# LPC55S66_cm33_core1 register map
Vendor: nxp.com; File version: 1.0
CPU: CM33 r2p0, little endian, no MPU, no FPU, VTOR, 3 interrupt priority bits
Registers are 32-bit, read-write, reset 0x0 unless marked. A register's access mark holds for its fields unless they carry their own. Offsets are from the block's base; [hi:lo] are bit positions; {n}, {i} and the like mark numbered series.

## UTICK0 — Micro-tick Timer (UTICK)
Base 0x4000E000
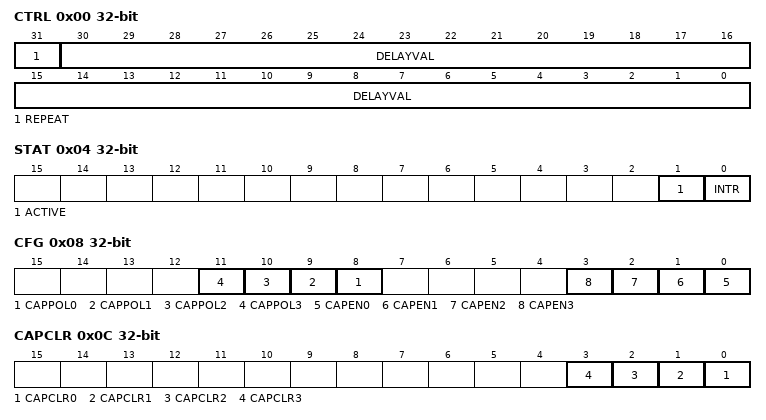
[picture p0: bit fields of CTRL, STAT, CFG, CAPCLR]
0x00 CTRL — Control register.
  [31] REPEAT — Repeat delay. 0 = One-time delay. 1 = Delay repeats continuously.
  [30:0] DELAYVAL — Tick interval value. The delay will be equal to DELAYVAL + 1 periods of the timer clock. The minimum usable value is 1, for a delay of 2 timer clocks. A value of 0 stops the timer.
0x04 STAT — Status register.
  [1] ACTIVE — Active flag. 0 = The Micro-Tick Timer is stopped. 1 = The Micro-Tick Timer is currently active.
  [0] INTR — Interrupt flag. 0 = No interrupt is pending. 1 = An interrupt is pending. A write of any value to this register clears this flag.
0x08 CFG — Capture configuration register.
  [n+8] CAPPOL{n} (n=0..3) — Capture Polarity {n}. 0 = Positive edge capture, 1 = Negative edge capture.
  [n] CAPEN{n} (n=0..3) — Enable Capture {n}. 1 = Enabled, 0 = Disabled.
0x0C CAPCLR wo reset not defined — Capture clear register.
  [n] CAPCLR{n} (n=0..3) — Clear capture {n}. Writing 1 to this bit clears the CAP{n} register value.
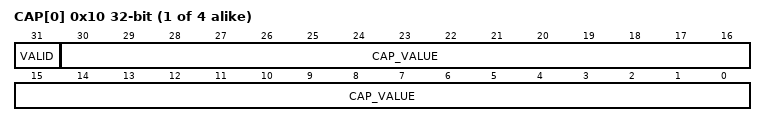
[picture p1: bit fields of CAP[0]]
{0x10+4i} CAP[{i}] (i=0..3) ro — Capture register .
  [31] VALID — Capture Valid. When 1, a value has been captured based on a transition of the related UTICK_CAPn pin. Cleared by writing to the related bit in the CAPCLR register.
  [30:0] CAP_VALUE — Capture value for the related capture event (UTICK_CAPn. Note: the value is 1 lower than the actual value of the Micro-tick Timer at the moment of the capture event.

## SYSCTL — system controller
Base 0x40023000
0x00 UPDATELCKOUT — update lock out control
  [0] UPDATELCKOUT — All Registers
    0=NORMAL_MODE (Normal Mode. Can be written to.); 1=PROTECTED_MODE (Protected Mode. Cannot be written to.)
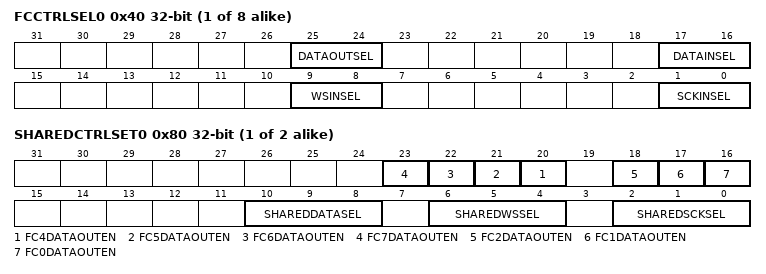
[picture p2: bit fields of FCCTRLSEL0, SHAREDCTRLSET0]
{0x40+4i} FCCTRLSEL{i} (i=0..7) — Selects the source for SCK going into Flexcomm 0
  [25:24] DATAOUTSEL — Selects the source for DATA output from this Flexcomm.
    0=ORIG_FLEX_I2S_SIGNALS (Selects the dedicated FCn_RXD_SDA_MOSI_DATA output from this Flexcomm.); 1=SHARED_SET0_I2S_SIGNALS (Output data is taken from shared signal set 0 (defined by SHAREDCTRLSET0).); 2=SHARED_SET1_I2S_SIGNALS (Output data is taken from shared signal set 1 (defined by SHAREDCTRLSET1).)
  [17:16] DATAINSEL — Selects the source for DATA input to this Flexcomm.
    0=ORIG_FLEX_I2S_SIGNALS (Selects the dedicated FCn_RXD_SDA_MOSI_DATA input for this Flexcomm.); 1=SHARED_SET0_I2S_SIGNALS (Input data is taken from shared signal set 0 (defined by SHAREDCTRLSET0).); 2=SHARED_SET1_I2S_SIGNALS (Input data is taken from shared signal set 1 (defined by SHAREDCTRLSET1).)
  [9:8] WSINSEL — Selects the source for WS going into this Flexcomm.
    0=ORIG_FLEX_I2S_SIGNALS (Selects the dedicated (FCn_TXD_SCL_MISO_WS) function for this Flexcomm.); 1=SHARED_SET0_I2S_SIGNALS (WS is taken from shared signal set 0 (defined by SHAREDCTRLSET0).); 2=SHARED_SET1_I2S_SIGNALS (WS is taken from shared signal set 1 (defined by SHAREDCTRLSET1).)
  [1:0] SCKINSEL rw-once — Selects the source for SCK going into this Flexcomm.
    0=ORIG_FLEX_I2S_SIGNALS (Selects the dedicated FCn_SCK function for this Flexcomm.); 1=SHARED_SET0_I2S_SIGNALS (SCK is taken from shared signal set 0 (defined by SHAREDCTRLSET0).); 2=SHARED_SET1_I2S_SIGNALS (SCK is taken from shared signal set 1 (defined by SHAREDCTRLSET1).)
{0x80+4i} SHAREDCTRLSET{i} (i=0..1) — Selects sources and data combinations for shared signal set 0.
  [n+16] FC{n}DATAOUTEN (n=4..7) — Controls FC{n} contribution to SHAREDDATAOUT for this shared set.
    0=INPUT (Data output from FC{n} does not contribute to this shared set.); 1=OUTPUT (Data output from FC{n} does contribute to this shared set.)
  [18] FC2DATAOUTEN — Controls FC2 contribution to SHAREDDATAOUT for this shared set.
    0=INPUT (Data output from FC2 does not contribute to this shared set.); 1=OUTPUT (Data output from FC2 does contribute to this shared set.)
  [17] FC1DATAOUTEN — Controls FC1 contribution to SHAREDDATAOUT for this shared set.
    0=INPUT (Data output from FC1 does not contribute to this shared set.); 1=OUTPUT (Data output from FC1 does contribute to this shared set.)
  [16] FC0DATAOUTEN — Controls FC0 contribution to SHAREDDATAOUT for this shared set.
    0=INPUT (Data output from FC0 does not contribute to this shared set.); 1=OUTPUT (Data output from FC0 does contribute to this shared set.)
  [10:8] SHAREDDATASEL — Selects the source for DATA input for this shared signal set.
    {v}=FLEXCOMM{v} (DATA input for this shared signal set comes from Flexcomm {v}.) (v=0..7)
  [6:4] SHAREDWSSEL — Selects the source for WS of this shared signal set.
    {v}=FLEXCOMM{v} (WS for this shared signal set comes from Flexcomm {v}.) (v=0..7)
  [2:0] SHAREDSCKSEL — Selects the source for SCK of this shared signal set.
    {v}=FLEXCOMM{v} (SCK for this shared signal set comes from Flexcomm {v}.) (v=0..7)
0x100 USB_HS_STATUS (reset mask 0x1C0FF00) — Status register for USB HS
  [0] USBHS_3V_NOK ro — USB_HS: Low voltage detection on 3.3V supply.
    0=SUPPLY_3V_OK (3v3 supply is good.); 1=SUPPLY_3V_LOW (3v3 supply is too low.)
